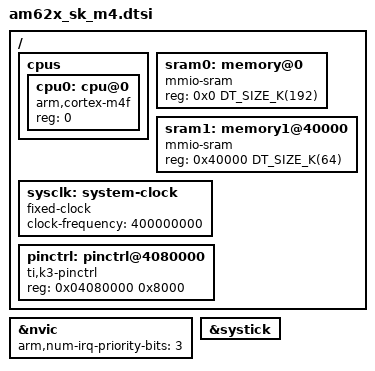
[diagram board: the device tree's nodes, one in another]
/*
 * Copyright (c) 2023 Texas Instruments Incorporated
 *
 * SPDX-License-Identifier: Apache-2.0
 */

#include <mem.h>
#include <freq.h>
#include <arm/armv7-m.dtsi>
#include <zephyr/dt-bindings/pinctrl/ti-k3-pinctrl.h>

/ {

	cpus {
		#address-cells = <1>;
		#size-cells = <0>;

		cpu0: cpu@0 {
			device_type = "cpu";
			compatible = "arm,cortex-m4f";
			reg = <0>;
		};
	};
	sram0: memory@0 {
		compatible = "mmio-sram";
		reg = <0x0 DT_SIZE_K(192)>;		/* 192 KB of SRAM (I-Code) */
	};

	sram1: memory1@40000 {
		compatible = "mmio-sram";
		reg = <0x40000 DT_SIZE_K(64)>;		/* 64 KB of SRAM (D-Code) */
	};


	sysclk: system-clock {
		compatible = "fixed-clock";
		clock-frequency = <400000000>;
		#clock-cells = <0>;
	};

	pinctrl: pinctrl@4080000 {
		compatible = "ti,k3-pinctrl";
		reg = <0x04080000 0x8000>;
		status = "okay";
	};
};

&nvic {
	arm,num-irq-priority-bits = <3>;
};

&systick {
	status = "okay";
};
